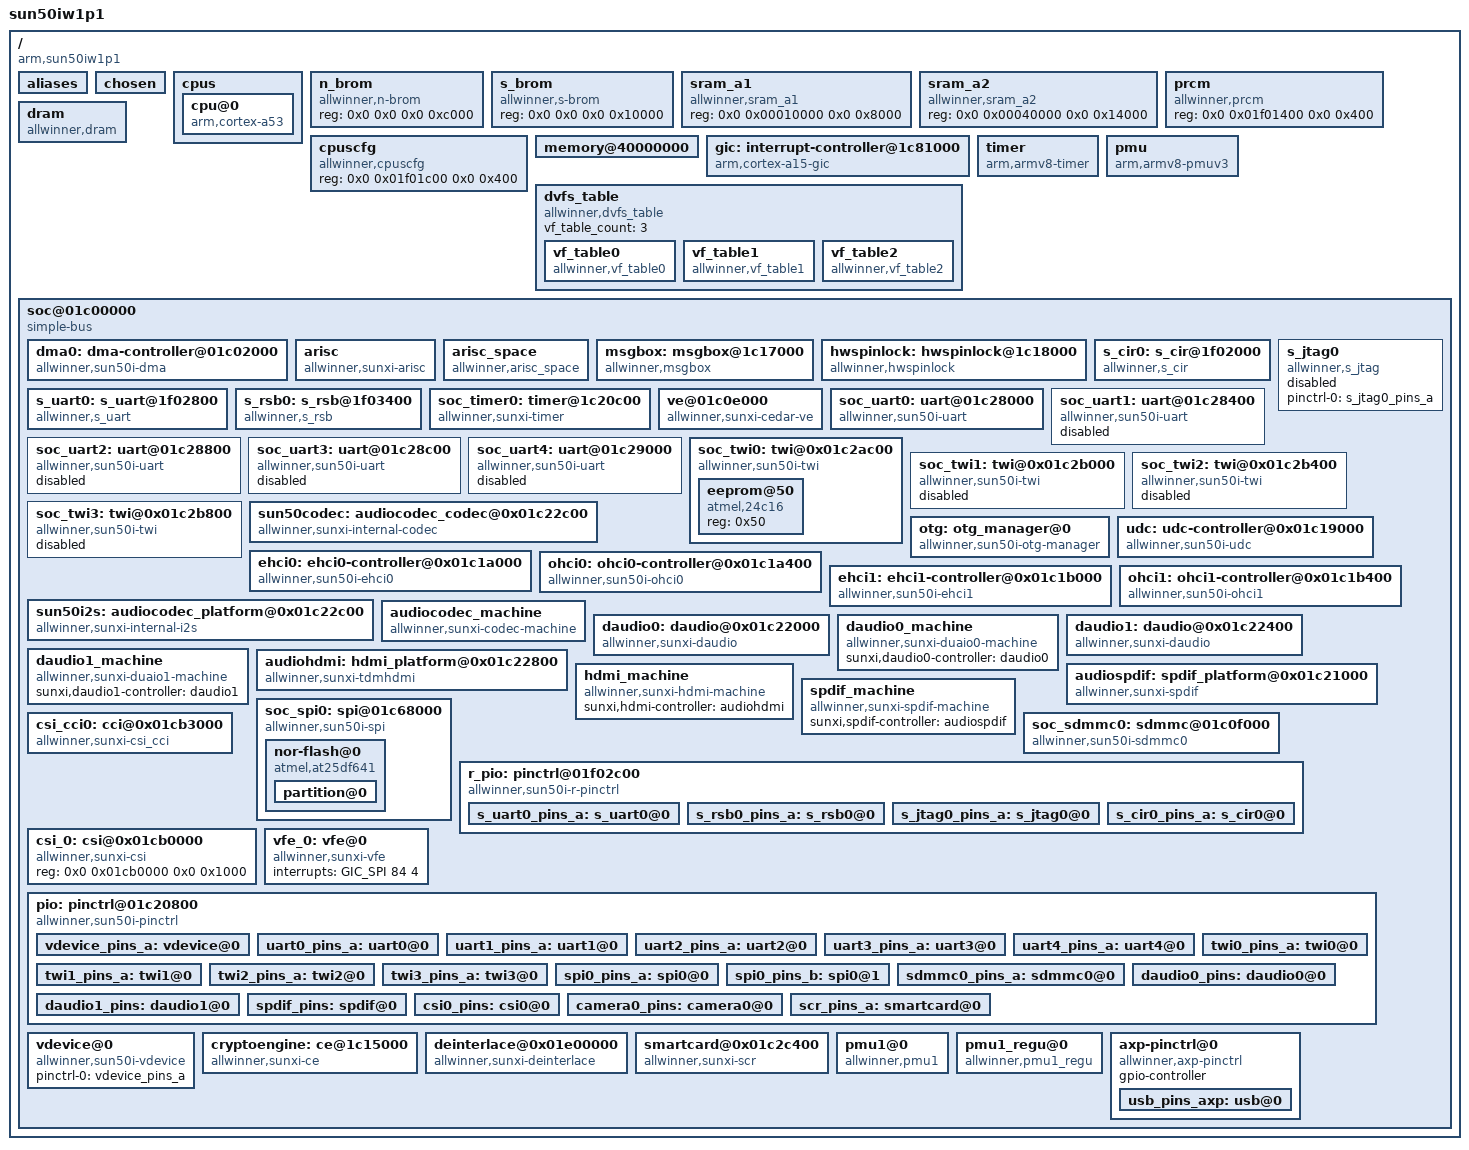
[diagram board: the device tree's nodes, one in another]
/*
 * Allwinner Technology CO., Ltd. sun50iw1p1 platform
 *
 * fpga support
 * modify base on juno.dts
 */

/dts-v1/;

/memreserve/ 0x40000000 0x00010000; /* sun50iw1p1.dtb range       : [0x40000000~0x40010000], size = 64K */
/memreserve/ 0x40010000 0x00010000; /* sys_config.fex range       : [0x40010000~0x40020000], size = 64K */
/memreserve/ 0x40020000 0x00004000; /* arisc dram code space range: [0x40020000~0x40024000], size = 16K */
/memreserve/ 0x40024000 0x00001000; /* arisc para cfg range       : [0x40024000~0x40025000], size = 4K  */
/memreserve/ 0x40025000 0x00000800; /* super standby range        : [0x40025000~0x40025800], size = 2K  */

#include <dt-bindings/interrupt-controller/arm-gic.h>
/include/"sun50iw1p1-clk.dtsi"

/ {
	model = "sun50iw1p1";
	compatible = "arm,sun50iw1p1", "arm,sun50iw1p1";
	interrupt-parent = <&gic>;
	#address-cells = <2>;
	#size-cells = <2>;

	aliases {
		serial0 = &soc_uart0;
		serial1 = &soc_uart1;
		serial2 = &soc_uart2;
		serial3 = &soc_uart3;
		serial4 = &soc_uart4;
		twi0 = &soc_twi0;
		twi1 = &soc_twi1;
		twi2 = &soc_twi2;
		twi3 = &soc_twi3;
		spi0 = &soc_spi0;
		global_timer0  = &soc_timer0;
		cci0 = &csi_cci0;
		csi0 = &csi_0;
		vfe0 = &vfe_0;
	};

	chosen {
		bootargs = "earlyprintk=sunxi-uart,0x01c28000 loglevel=8 initcall_debug=1 memblock=debug console=ttyS0 init=/init";
    };

	cpus {
		#address-cells = <2>;
		#size-cells = <0>;

		cpu@0 {
			device_type = "cpu";
			compatible = "arm,cortex-a53","arm,armv8";
			reg = <0x0 0x0>;
			enable-method = "psci";
			cpufreq_tbl = <  480000
							 600000
							 720000
							 816000
							1008000
							1200000
							1344000>;
			clock-latency = <2000000>;
		};
	};

	n_brom {
		compatible = "allwinner,n-brom";
		reg = <0x0 0x0 0x0 0xc000>;
	};

	s_brom {
		compatible = "allwinner,s-brom";
		reg = <0x0 0x0 0x0 0x10000>;
	};

	sram_a1 {
		compatible = "allwinner,sram_a1";
		reg = <0x0 0x00010000 0x0 0x8000>;
	};

	sram_a2 {
		compatible = "allwinner,sram_a2";
		reg = <0x0 0x00040000 0x0 0x14000>;
	};

	prcm {
		compatible = "allwinner,prcm";
		reg = <0x0 0x01f01400 0x0 0x400>;
	};

	cpuscfg {
		compatible = "allwinner,cpuscfg";
		reg = <0x0 0x01f01c00 0x0 0x400>;
	};

	dram {
		compatible = "allwinner,dram";
		clocks = <&clk_pll_ddr0>, <&clk_pll_ddr1>;
		clock-names = "pll_ddr0", "pll_ddr1";
		dram_clk        = <672>;
		dram_type       = <3>;
		dram_zq         = <0x003F3FDD>;
		dram_odt_en     = <1>;
		dram_para1      = <0x10f41000>;
		dram_para2      = <0x00001200>;
		dram_mr0        = <0x1A50>;
		dram_mr1        = <0x40>;
		dram_mr2        = <0x10>;
		dram_mr3        = <0>;
		dram_tpr0       = <0x04E214EA>;
		dram_tpr1       = <0x004214AD>;
		dram_tpr2       = <0x10A75030>;
		dram_tpr3       = <0>;
		dram_tpr4       = <0>;
		dram_tpr5       = <0>;
		dram_tpr6       = <0>;
		dram_tpr7       = <0>;
		dram_tpr8       = <0>;
		dram_tpr9       = <0>;
		dram_tpr10      = <0>;
		dram_tpr11      = <0>;
		dram_tpr12      = <168>;
		dram_tpr13      = <0x823>;
	};

	memory@40000000 {
		device_type = "memory";
		reg = <0x00000000 0x40000000 0x00000000 0x40000000>;
	};

	gic: interrupt-controller@1c81000 {
		compatible = "arm,cortex-a15-gic", "arm,cortex-a9-gic";
		#interrupt-cells = <3>;
		#address-cells = <0>;
		interrupt-controller;
		reg = <0x0 0x01c81000 0 0x1000>, /* GIC Dist */
		      <0x0 0x01c82000 0 0x2000>, /* GIC CPU */
		      <0x0 0x01c84000 0 0x2000>, /* GIC VCPU Control */
		      <0x0 0x01c86000 0 0x2000>; /* GIC VCPU */
		interrupts = <GIC_PPI 9 0xf04>; /* GIC Maintenence IRQ */
	};

	timer {
		compatible = "arm,armv8-timer";
		interrupts = <GIC_PPI 13 0xff01>, /* Secure Phys IRQ */
			     <GIC_PPI 14 0xff01>, /* Non-secure Phys IRQ */
			     <GIC_PPI 11 0xff01>, /* Virt IRQ */
			     <GIC_PPI 10 0xff01>; /* Hyp IRQ */
		clock-frequency = <24000000>;
	};

	pmu {
		compatible = "arm,armv8-pmuv3";
		interrupts = <GIC_SPI 120 4>,
			     <GIC_SPI 121 4>,
			     <GIC_SPI 122 4>,
			     <GIC_SPI 123 4>;
	};

	dvfs_table {
		compatible = "allwinner,dvfs_table";
		vf_table_count = <3>;

		vf_table0 {
			compatible = "allwinner,vf_table0";
			max_freq = <1200000000>;
			min_freq = <60000000>;
			LV_count = <8>;
			LV1_freq = <1200000000>;
			LV1_volt = <1300>;
			LV2_freq = <1104000000>;
			LV2_volt = <1200>;
			LV3_freq = <1008000000>;
			LV3_volt = <1100>;
			LV4_freq = <816000000>;
			LV4_volt = <1000>;
			LV5_freq = <600000000>;
			LV5_volt = <900>;
			LV6_freq = <0>;
			LV6_volt = <900>;
			LV7_freq = <0>;
			LV7_volt = <900>;
			LV8_freq = <0>;
			LV8_volt = <900>;
		};

		vf_table1 {
			compatible = "allwinner,vf_table1";
			max_freq = <1200000000>;
			min_freq = <60000000>;
			LV_count = <8>;
			LV1_freq = <1200000000>;
			LV1_volt = <1300>;
			LV2_freq = <1104000000>;
			LV2_volt = <1200>;
			LV3_freq = <1008000000>;
			LV3_volt = <1100>;
			LV4_freq = <816000000>;
			LV4_volt = <1000>;
			LV5_freq = <600000000>;
			LV5_volt = <900>;
			LV6_freq = <0>;
			LV6_volt = <900>;
			LV7_freq = <0>;
			LV7_volt = <900>;
			LV8_freq = <0>;
			LV8_volt = <900>;
		};

		vf_table2 {
			compatible = "allwinner,vf_table2";
			max_freq = <1200000000>;
			min_freq = <60000000>;
			LV_count = <8>;
			LV1_freq = <1200000000>;
			LV1_volt = <1300>;
			LV2_freq = <1104000000>;
			LV2_volt = <1200>;
			LV3_freq = <1008000000>;
			LV3_volt = <1100>;
			LV4_freq = <816000000>;
			LV4_volt = <1000>;
			LV5_freq = <600000000>;
			LV5_volt = <900>;
			LV6_freq = <0>;
			LV6_volt = <900>;
			LV7_freq = <0>;
			LV7_volt = <900>;
			LV8_freq = <0>;
			LV8_volt = <900>;
		};
	};

	soc@01c00000 {
		compatible = "simple-bus";
		#address-cells = <2>;
		#size-cells = <2>;
		ranges;

		dma0:dma-controller@01c02000 {
			compatible = "allwinner,sun50i-dma";
			reg = <0x0 0x01c02000 0x0 0x1000>;
			interrupts = <0 50 4>;
			clocks = <&clk_dma>;
			#dma-cells = <1>;
		};

		arisc {
			compatible = "allwinner,sunxi-arisc";
			#address-cells = <2>;
			#size-cells = <2>;
			clocks = <&clk_losc>, <&clk_iosc>, <&clk_hosc>, <&clk_pll_periph0>;
			clock-names = "losc", "iosc", "hosc", "pll_periph0";
			powchk_used = <0x0>;
			power_reg = <0x02309621>;
			system_power = <50>;
		};

		arisc_space {
			compatible = "allwinner,arisc_space";
			/* num    dst        offset     size                              */
			space1 = <0x00040000 0x00000000 0x00014000>; /* srama2 code space */
			space2 = <0x40020000 0x00018000 0x00004000>; /* dram code space   */
			space3 = <0x40024000 0x00000000 0x00001000>; /* para space        */
		};

		msgbox: msgbox@1c17000 {
			compatible = "allwinner,msgbox";
			clocks = <&clk_msgbox>;
			clock-names = "clk_msgbox";
			reg = <0x0 0x01c17000 0x0 0x1000>;
			interrupts = <GIC_SPI 49 IRQ_TYPE_EDGE_RISING>;
			status = "okay";
		};

		hwspinlock: hwspinlock@1c18000 {
			compatible = "allwinner,hwspinlock";
			clocks = <&clk_spinlock>;
			clock-names = "clk_spinlock";
			reg = <0x0 0x01c18000 0x0 0x1000>;
			status = "okay";
		};

		s_cir0: s_cir@1f02000 {
			compatible = "allwinner,s_cir";
			reg = <0x0 0x01f02000 0x0 0x400>;
			interrupts = <GIC_SPI 37 IRQ_TYPE_LEVEL_HIGH>;
			pinctrl-names = "default";
			pinctrl-0 = <&s_cir0_pins_a>;
			ir_power_key_code = <0>;
			ir_addr_code = <0>;
			status = "okay";
		};

		s_uart0: s_uart@1f02800 {
			compatible = "allwinner,s_uart";
			reg = <0x0 0x01f02800 0x0 0x400>;
			interrupts = <GIC_SPI 38 IRQ_TYPE_LEVEL_HIGH>;
			pinctrl-names = "default";
			pinctrl-0 = <&s_uart0_pins_a>;
			status = "okay";
		};

		s_rsb0: s_rsb@1f03400 {
			compatible = "allwinner,s_rsb";
			reg = <0x0 0x01f03400 0x0 0x400>;
			interrupts = <GIC_SPI 39 IRQ_TYPE_LEVEL_HIGH>;
			pinctrl-names = "default";
			pinctrl-0 = <&s_rsb0_pins_a>;
			status = "okay";
		};

		s_jtag0 {
			compatible = "allwinner,s_jtag";
			pinctrl-names = "default";
			pinctrl-0 = <&s_jtag0_pins_a>;
			status = "disable";
		};

		soc_timer0: timer@1c20c00 {
			compatible = "allwinner,sunxi-timer";
			reg = <0x0 0x01c20c00 0x0 0x90>;
			interrupts = <GIC_SPI 18 IRQ_TYPE_EDGE_RISING>;
			clock-frequency = <24000000>;
			timer-prescale = <16>;
		};

		ve@01c0e000 {		
			compatible = "allwinner,sunxi-cedar-ve";		
			reg = <0x0 0x01c0e000 0x0 0x1000>,
					<0x0 0x01c00000 0x0 0x10>,
					<0x0 0x01c20000 0x0 0x800>;		
			interrupts = <GIC_SPI 58 4>;
			clocks = <&clk_pll_ve>,		
							<&clk_ve>;				

		};

		soc_uart0: uart@01c28000 {
			compatible = "allwinner,sun50i-uart";
			reg = <0x0 0x01c28000 0x0 0x400>;
			interrupts = <GIC_SPI 0 IRQ_TYPE_LEVEL_HIGH>;
			clocks = <&clk_uart0>;
			pinctrl-names = "default";
			pinctrl-0 = <&uart0_pins_a>;
			port-number = <0>;
			io-number = <2>;
			status = "okay";
		};

		soc_uart1: uart@01c28400 {
			compatible = "allwinner,sun50i-uart";
			reg = <0x0 0x01c28400 0x0 0x400>;
			interrupts = <GIC_SPI 1 IRQ_TYPE_LEVEL_HIGH>;
			clocks = <&clk_uart1>;
			pinctrl-names = "default";
			pinctrl-0 = <&uart1_pins_a>;
			port-number = <1>;
			io-number = <4>;
			status = "disabled";
		};

		soc_uart2: uart@01c28800 {
			compatible = "allwinner,sun50i-uart";
			reg = <0x0 0x01c28800 0x0 0x400>;
			interrupts = <GIC_SPI 2 IRQ_TYPE_LEVEL_HIGH>;
			clocks = <&clk_uart2>;
			pinctrl-names = "default";
			pinctrl-0 = <&uart2_pins_a>;
			port-number = <1>;
			io-number = <4>;
			status = "disabled";
		};

		soc_uart3: uart@01c28c00 {
			compatible = "allwinner,sun50i-uart";
			reg = <0x0 0x01c28c00 0x0 0x400>;
			interrupts = <GIC_SPI 3 IRQ_TYPE_LEVEL_HIGH>;
			clocks = <&clk_uart3>;
			pinctrl-names = "default";
			pinctrl-0 = <&uart3_pins_a>;
			port-number = <1>;
			io-number = <4>;
			status = "disabled";
		};

		soc_uart4: uart@01c29000 {
			compatible = "allwinner,sun50i-uart";
			reg = <0x0 0x01c29000 0x0 0x400>;
			interrupts = <GIC_SPI 4 IRQ_TYPE_LEVEL_HIGH>;
			clocks = <&clk_uart4>;
			pinctrl-names = "default";
			pinctrl-0 = <&uart4_pins_a>;
			port-number = <1>;
			io-number = <4>;
			status = "disabled";
		};
		
		soc_twi0: twi@0x01c2ac00{
			#address-cells = <1>;
			#size-cells = <0>;
			compatible = "allwinner,sun50i-twi";
			reg = <0x0 0x01c2ac00 0x0 0x400>;
			interrupts = <GIC_SPI 6 IRQ_TYPE_LEVEL_HIGH>;
			clocks = <&clk_twi0>;
			clock-frequency = <400000>;
			pinctrl-names = "default";
			pinctrl-0 = <&twi0_pins_a>;
			status = "okay";

			eeprom@50 {
				compatible = "atmel,24c16";
				reg = <0x50>;
			};
		};

		soc_twi1: twi@0x01c2b000{
			#address-cells = <1>;
			#size-cells = <0>;
			compatible = "allwinner,sun50i-twi";
			reg = <0x0 0x01c2b000 0x0 0x400>;
			interrupts = <GIC_SPI 7 IRQ_TYPE_LEVEL_HIGH>;
			clocks = <&clk_twi1>;
			clock-frequency = <200000>;
			pinctrl-names = "default";
			pinctrl-0 = <&twi1_pins_a>;
			status = "disable";
		};

		soc_twi2: twi@0x01c2b400{
			#address-cells = <1>;
			#size-cells = <0>;
			compatible = "allwinner,sun50i-twi";
			reg = <0x0 0x01c2b400 0x0 0x400>;
			interrupts = <GIC_SPI 8 IRQ_TYPE_LEVEL_HIGH>;
			clocks = <&clk_twi2>;
			clock-frequency = <200000>;
			pinctrl-names = "default";
			pinctrl-0 = <&twi2_pins_a>;
			status = "disable";
		};

		soc_twi3: twi@0x01c2b800{
			#address-cells = <1>;
			#size-cells = <0>;
			compatible = "allwinner,sun50i-twi";
			reg = <0x0 0x01c2b800 0x0 0x400>;
			interrupts = <GIC_SPI 9 IRQ_TYPE_LEVEL_HIGH>;
			clocks = <&clk_twi3>;
			clock-frequency = <200000>;
			pinctrl-names = "default";
			pinctrl-0 = <&twi3_pins_a>;
			status = "disable";
		};
		sun50codec:audiocodec_codec@0x01c22c00 {
			compatible = "allwinner,sunxi-internal-codec";
			reg = <0x0 0x01c22c00 0x0 0x478>,/*digital baseadress*/
			      <0x0 0x01f015c0 0x0 0x0>;/*analog baseadress*/
			clocks = <&clk_pll_audiox4>;
			allwinner,headphonevol = /bits/ 8 <0x3b>;
			allwinner,spkervol = /bits/ 8 <0x1b>;
			allwinner,earpiecevol = /bits/ 8 <0x1e>;
			allwinner,maingain = /bits/ 8 <0x4>;
			allwinner,headsetmicgain = /bits/ 8 <0x4>;
			allwinner,adcagc_used = /bits/ 8 <0x0>;
			allwinner,adcdrc_used = /bits/ 8 <0x0>;
			allwinner,adchpf_used = /bits/ 8 <0x0>;
			allwinner,dacdrc_used = /bits/ 8 <0x0>;
			allwinner,dachpf_used = /bits/ 8 <0x0>;

			allwinner,aif2config = /bits/ 8 <0x0>;
			allwinner,aif3config = /bits/ 8 <0x0>;
			status = "okay";
		};

		otg:otg_manager@0 {
			compatible          = "allwinner,sun50i-otg-manager";
			usb_used            = <1>;
			usb_port_type       = <2>;
			usb_id_gpio         = <&pio 0 0 0>; /*PB0*/
			usb_det_vbus_gpio   = "axp_ctrl"; /*PB1*/
		};

		udc:udc-controller@0x01c19000 {
			compatible          = "allwinner,sun50i-udc";
			reg                 = <0x0 0x01c19000 0x0 0x1000>, /*udc base*/
			                      <0x0 0x01c00000 0x0 0x100>; /*sram base*/
			interrupts          = <0 71 4>;
			clocks              = <&clk_usbphy0>, <&clk_usbotg>;
			usb_used            = <1>;
			luns                = <3>;
			serial_unique       = <0>;
			serial_number       = "20080411";
		};

		ehci0:ehci0-controller@0x01c1a000 {
			compatible          = "allwinner,sun50i-ehci0";
			reg                 = <0x0 0x01c1a000 0x0 0x900>, /*udc base*/
			                      <0x0 0x01c00000 0x0 0x100>, /*sram base*/
			                      <0x0 0x01c19000 0x0 0x1000>; /*otg base*/
			interrupts          = <0 72 4>;
			clocks              = <&clk_usbphy0>, <&clk_usbehci0>;
			hci_ctrl_no         = <0>;
			usb_used            = <1>;
			usb_drv_vbus_gpio   = <&pio 0 0 0>; /*PA0*/
			usb_host_init_state = <0>;
			usb_regulator_io    = "nocare";
			usb_regulator_vol   = <0>;
			usb_wakeup_suspend  = <0>;
		};

		ohci0:ohci0-controller@0x01c1a400 {
			compatible          = "allwinner,sun50i-ohci0";
			reg                 = <0x0 0x01c1a400 0x0 0x500>, /*udc base*/
			                      <0x0 0x01c00000 0x0 0x100>, /*sram base*/
			                      <0x0 0x01c19000 0x0 0x1000>; /*otg base*/
			interrupts          = <0 73 4>;
			clocks              = <&clk_usbphy0>, <&clk_usbohci0>;
			hci_ctrl_no         = <0>;
			usb_used            = <1>;
			usb_drv_vbus_gpio   = <&pio 0 0 0>; /*PA0*/
			usb_host_init_state = <0>;
			usb_regulator_io    = "nocare";
			usb_regulator_vol   = <0>;
			usb_wakeup_suspend   = <0>;
		};

		ehci1:ehci1-controller@0x01c1b000 {
			compatible          = "allwinner,sun50i-ehci1";
			reg                 = <0x0 0x01c1b000 0x0 0x900>;/*udc base*/
			interrupts          = <0 74 4>;
			clocks              = <&clk_usbphy1>, <&clk_usbehci1>;
			hci_ctrl_no         = <1>;
			usb_used            = <1>;
			usb_drv_vbus_gpio   = <&pio 0 0 0>; /*PA1*/
			usb_host_init_state = <1>;
			usb_regulator_io    = "nocare";
			usb_regulator_vol   = <0>;
			usb_wakeup_suspend     = <0>;
		};

		ohci1:ohci1-controller@0x01c1b400 {
			compatible          = "allwinner,sun50i-ohci1";
			reg                 = <0x0 0x01c1b400 0x0 0x500>;/*udc base*/
			interrupts          = <0 75 4>;
			clocks              = <&clk_usbphy1>, <&clk_usbohci1>;
			hci_ctrl_no         = <1>;
			usb_used            = <1>;
			usb_drv_vbus_gpio   = <&pio 0 0 0>; /*PA1*/
			usb_host_init_state = <1>;
			usb_regulator_io    = "nocare";
			usb_regulator_vol   = <0>;
			usb_wakeup_suspend  = <0>;
		};

		sun50i2s:audiocodec_platform@0x01c22c00 {
			compatible = "allwinner,sunxi-internal-i2s";
			reg = <0x0 0x01c22c00 0x0 0x478>;/*digital baseadress*/
			clocks = <&clk_pll_audio>,<&clk_adda>;
			status = "okay";
		};

		audiocodec_machine{
			compatible = "allwinner,sunxi-codec-machine";
			interrupts = <GIC_SPI 61 0x101>;
			sunxi,i2s-controller = <&sun50i2s>;
			sunxi,audio-codec = <&sun50codec>;
			status = "okay";
		};

		daudio0:daudio@0x01c22000 {
			compatible = "allwinner,sunxi-daudio";
			reg = <0x0 0x01c22000 0x0 0x58>;
			clocks = <&clk_pll_audio>,<&clk_i2s0>;
			pinctrl-names = "default";
			pinctrl-0 = <&daudio0_pins>;
			allwinner,pcm_lrck_period = /bits/ 8 <0x20>;
			allwinner,pcm_lrckr_period = /bits/ 8 <0x01>;
			allwinner,slot_width_select = /bits/ 8 <0x10>;
			allwinner,pcm_lsb_first = /bits/ 8 <0x0>;
			allwinner,tx_data_mode = /bits/ 8 <0x0>;
			allwinner,rx_data_mode = /bits/ 8 <0x0>;
			allwinner,daudio_master = /bits/ 8 <0x04>;
			allwinner,audio_format = /bits/ 8 <0x01>;
			allwinner,signal_inversion = /bits/ 8 <0x01>;
			allwinner,frametype = /bits/ 8 <0x0>;
			allwinner,tdm_config = /bits/ 8 <0x01>;
			status = "okay";
		};
		daudio0_machine{
			compatible = "allwinner,sunxi-duaio0-machine";
			sunxi,daudio0-controller = <&daudio0>;
			status = "okay";
		};
		daudio1:daudio@0x01c22400 {
			compatible = "allwinner,sunxi-daudio";
			reg = <0x0 0x01c22400 0x0 0x58>;
			pinctrl-names = "default";
			pinctrl-0 = <&daudio1_pins>;
			clocks = <&clk_pll_audio>,<&clk_i2s1>;
			allwinner,pcm_lrck_period = /bits/ 8 <0x20>;
			allwinner,pcm_lrckr_period = /bits/ 8 <0x01>;
			allwinner,slot_width_select = /bits/ 8 <0x10>;
			allwinner,pcm_lsb_first = /bits/ 8 <0x0>;
			allwinner,tx_data_mode = /bits/ 8 <0x0>;
			allwinner,rx_data_mode = /bits/ 8 <0x0>;
			allwinner,daudio_master = /bits/ 8 <0x04>;
			allwinner,audio_format = /bits/ 8 <0x01>;
			allwinner,signal_inversion = /bits/ 8 <0x01>;
			allwinner,frametype = /bits/ 8 <0x0>;
			allwinner,tdm_config = /bits/ 8 <0x01>;
			status = "okay";
		};
		daudio1_machine{
			compatible = "allwinner,sunxi-duaio1-machine";
			sunxi,daudio1-controller = <&daudio1>;
			status = "okay";
		};
		audiohdmi:hdmi_platform@0x01c22800{
			compatible = "allwinner,sunxi-tdmhdmi";
			reg = <0x0 0x01c22800 0x0 0x58>;
			clocks = <&clk_pll_audio>,<&clk_i2s2>;
			status = "okay";
		};
		hdmi_machine{
			compatible = "allwinner,sunxi-hdmi-machine";
			sunxi,hdmi-controller = <&audiohdmi>;
			status = "okay";
		};
		audiospdif:spdif_platform@0x01c21000{
			compatible = "allwinner,sunxi-spdif";
			reg = <0x0 0x01c21000 0x0 0x38>;
			clocks = <&clk_pll_audio>,<&clk_spdif>;
			pinctrl-names = "default";
			pinctrl-0 = <&spdif_pins>;
			status = "okay";
		};
		spdif_machine{
			compatible = "allwinner,sunxi-spdif-machine";
			sunxi,spdif-controller = <&audiospdif>;
			status = "okay";
		};
	
		soc_spi0: spi@01c68000 {
			#address-cells = <1>;
			#size-cells = <0>;
			compatible = "allwinner,sun50i-spi";
			reg = <0x0 0x01c68000 0x0 0x1000>;
			interrupts = <GIC_SPI 65 IRQ_TYPE_LEVEL_HIGH>;
			clocks = <&clk_pll_periph0>, <&clk_spi0>;
			pinctrl-names = "default";
			pinctrl-0 = <&spi0_pins_a>, <&spi0_pins_b>;
			cs-number = <1>;
			cs-bitmap = <1>;
			status = "okay";

			nor-flash@0 {
				#address-cells = <1>;
				#size-cells = <1>;
				compatible = "atmel,at25df641";
				reg = <0>;	/* Chip select 0 */
				spi-max-frequency = <50000000>;
				mode = <0>;

				partition@0 {
					label = "NorFlash part0";
					reg = <0x00000000 0x0002000>;
				};
			};
		};

		soc_sdmmc0: sdmmc@01c0f000 {
			compatible = "allwinner,sun50i-sdmmc0";
			reg = <0x0 0x01c0f000 0x0 0x1000>; /* only sdmmc0 */
			interrupts = <GIC_SPI 60 0x0104>;  /*  */
			clocks = <&clk_hosc>,<&clk_pll_periph0>,<&clk_sdmmc0>;
			pinctrl-names = "default";
			pinctrl-0 = <&sdmmc0_pins_a>;
			status = "okay";
		};
		r_pio: pinctrl@01f02c00 {
			compatible = "allwinner,sun50i-r-pinctrl";
			reg = <0x0 0x01f02c00 0x0 0x400>;
			interrupts = <GIC_SPI 35 4>;
			clocks = <&clk_cpurpio>;
			//resets = <&apb0_rst 0>;
			gpio-controller;
			interrupt-controller;
			#interrupt-cells = <2>;
			#size-cells = <0>;
			#gpio-cells = <3>;

			s_uart0_pins_a: s_uart0@0 {
				allwinner,pins = "PL2", "PL3";
				allwinner,function = "s_uart0";
				allwinner,drive = <1>;
				allwinner,pull = <1>;
			};

			s_rsb0_pins_a: s_rsb0@0 {
				allwinner,pins = "PL0", "PL1";
				allwinner,function = "s_rsb0";
				allwinner,drive = <2>;
				allwinner,pull = <1>;
			};

			s_jtag0_pins_a: s_jtag0@0 {
				allwinner,pins = "PL4", "PL5", "PL6", "PL7";
				allwinner,function = "s_jtag0";
				allwinner,drive = <2>;
				allwinner,pull = <1>;
			};

			s_cir0_pins_a: s_cir0@0 {
				allwinner,pins = "PL11";
				allwinner,function = "s_cir0";
				allwinner,drive = <2>;
				allwinner,pull = <1>;
			};
		};
		
		csi_cci0:cci@0x01cb3000 {
			compatible = "allwinner,sunxi-csi_cci";
			reg = <0x0 0x01cb3000 0x0 0x1000>;	/*0x01cb3000--0x01cb4000*/
			interrupts = <GIC_SPI 122 4>;/*SUNXI_IRQ_CSI0_CCI (SUNXI_GIC_START + 122)*/
			status = "okay";
		};		
		csi_0:csi@0x01cb0000 {
			compatible = "allwinner,sunxi-csi";
			reg = <0x0 0x01cb0000 0x0 0x1000>;/*0x01cb0000--0x01cb1000*/
			status = "okay";
		};
		vfe_0:vfe@0 {
			compatible = "allwinner,sunxi-vfe";
			interrupts = <GIC_SPI 84 4>;/*SUNXI_IRQ_CSI0 (SUNXI_GIC_START + 84 )*/
			status = "okay";
		};
		
		pio: pinctrl@01c20800 {
			compatible = "allwinner,sun50i-pinctrl";
			reg = <0x0 0x01c20800 0x0 0x400>;
			interrupts =	<GIC_SPI 11 4>,
					<GIC_SPI 17 4>,
					<GIC_SPI 21 4>;
			clocks = <&clk_pio>;
			gpio-controller;
			interrupt-controller;
			#interrupt-cells = <2>;
			#size-cells = <0>;
			#gpio-cells = <3>;
			vdevice_pins_a: vdevice@0 {
				allwinner,pins = "PB0", "PB1";
				allwinner,function = "vdevice";
				allwinner,drive = <1>;
				allwinner,pull = <1>;
			};
			uart0_pins_a: uart0@0 {
				allwinner,pins = "PB8", "PB9";
				allwinner,function = "uart0";
				allwinner,drive = <1>;
				allwinner,pull = <0>;
			};
			uart1_pins_a: uart1@0 {
				allwinner,pins = "PG6", "PG7", "PG8", "PG9";
				allwinner,function = "uart1";
				allwinner,drive = <1>;
				allwinner,pull = <0>;
			};
			uart2_pins_a: uart2@0 {
				allwinner,pins = "PB0", "PB1", "PB2", "PB3";
				allwinner,function = "uart2";
				allwinner,drive = <1>;
				allwinner,pull = <0>;
			};
			uart3_pins_a: uart3@0 {
				allwinner,pins = "PH4", "PH5", "PH6", "PH7";
				allwinner,function = "uart3";
				allwinner,drive = <1>;
				allwinner,pull = <0>;
			};
			uart4_pins_a: uart4@0 {
				allwinner,pins = "PD2", "PD3", "PD4", "PD5";
				allwinner,function = "uart4";
				allwinner,drive = <1>;
				allwinner,pull = <0>;
			};

			twi0_pins_a: twi0@0 {
				//allwinner,pins = "PH0", "PH1";
				allwinner,pins = "PB0", "PB1";	// for fpga
				allwinner,function = "twi0";
				allwinner,drive = <1>;
				allwinner,pull = <0>;
			};
			twi1_pins_a: twi1@0 {
				allwinner,pins = "PH2", "PH3";
				allwinner,function = "twi1";
				allwinner,drive = <1>;
				allwinner,pull = <0>;
			};
			twi2_pins_a: twi2@0 {
				allwinner,pins = "PE14", "PE15";
				allwinner,function = "twi2";
				allwinner,drive = <1>;
				allwinner,pull = <0>;
			};
			twi3_pins_a: twi3@0 {
				allwinner,pins = "PE16", "PE17";
				allwinner,function = "twi3";
				allwinner,drive = <1>;
				allwinner,pull = <0>;
			};
			spi0_pins_a: spi0@0 {
				allwinner,pins = "PC0", "PC1", "PC2";
				allwinner,function = "spi0";
				allwinner,drive = <1>;
				allwinner,pull = <0>;
			};
			spi0_pins_b: spi0@1 {
				allwinner,pins = "PC3";
				allwinner,function = "spi0";
				allwinner,drive = <1>;
				allwinner,pull = <1>; 	// only CS should be pulled up
			};

			sdmmc0_pins_a: sdmmc0@0 {
				allwinner,pins = "PF0", "PF1", "PF2", "PF3","PF4","PF5";
				allwinner,function = "sdc0";
				allwinner,drive = <1>;
				allwinner,pull = <1>;
			};		
			daudio0_pins: daudio0@0 {
				allwinner,pins = "PB6", "PB3", "PB4", "PB5", "PB7";
				allwinner,function = "pcm0";
				allwinner,drive = <1>;
				allwinner,pull = <0>;
			};
			daudio1_pins: daudio1@0 {
				allwinner,pins = "PG10", "PG11", "PG12", "PG13";
				allwinner,function = "pcm1";
				allwinner,drive = <1>;
				allwinner,pull = <0>;
			};	
			spdif_pins: spdif@0 {
				allwinner,pins = "PH8";/*ph8-spec*/
				allwinner,function = "spdif0";
				allwinner,drive = <1>;
				allwinner,pull = <0>;
			};		
			csi0_pins: csi0@0 {
				allwinner,pins = "PE0","PE1","PE2","PE3","PE4","PE5","PE6","PE7","PE8","PE9","PE10","PE11","PE12","PE13";
				allwinner,function = "csi0";
				allwinner,drive = <1>;
				allwinner,pull = <0>;
			};
			camera0_pins: camera0@0 {
				allwinner,pins = "PE16","PE17";
				allwinner,function = "gpio_out";
				allwinner,drive = <1>;
				allwinner,pull = <0>;
			};						
			scr_pins_a: smartcard@0 {
				allwinner,pins = "PB1", "PB4", "PB5", "PB6","PB7";
				allwinner,function = "sim0";
				allwinner,drive = <1>;
				allwinner,pull = <1>;
			};
		};
		vdevice@0{
			compatible = "allwinner,sun50i-vdevice";
			pinctrl-names = "default";
			pinctrl-0 = <&vdevice_pins_a>;
			status = "okay";
		};
		cryptoengine: ce@1c15000 {
			compatible = "allwinner,sunxi-ce";
			reg = <0x0 0x01c15000 0x0 0x80>, /* non-secure space */
				  <0x0 0x01c15800 0x0 0x80>; /* secure space */
			interrupts = <GIC_SPI 94 0xff01>, /* non-secure space */
						 <GIC_SPI 80 0xff01>; /* secure space */
			clock-frequency = <300000000>, /* 300MHz */
							  <200000000>; /* 200MHz for RSA */
			clocks = <&clk_ce>,
					 <&clk_pll_periph0>;
		};
		deinterlace@0x01e00000{
			#address-cells = <1>;
			#size-cells = <0>;
			compatible = "allwinner,sunxi-deinterlace";
			reg = <0x0 0x01e00000 0x0 0x77c>;
			interrupts = <GIC_SPI 93 IRQ_TYPE_LEVEL_HIGH>;
			clocks = <&clk_deinterlace> ,<&clk_pll_periph0>;
			status = "okay";
		};
		smartcard@0x01c2c400{
			#address-cells = <1>;
			#size-cells = <0>;
			compatible = "allwinner,sunxi-scr";
			reg = <0x0 0x01c2c400 0x0 0x77c>;
			interrupts = <GIC_SPI 83 IRQ_TYPE_LEVEL_HIGH>;
			clocks = <&clk_scr>, <&clk_apb2>;
			clock-frequency = <24000000>;
			pinctrl-names = "default";
			pinctrl-0 = <&scr_pins_a>;
			status = "okay";
		};
		pmu1@0{
			compatible = "allwinner,pmu1";
			pmu_batdeten               = <1>;
			pmu_init_chgend_rate       = <20>;
			pmu_init_chg_enabled       = <1>;
			pmu_init_adc_freq          = <800>;
			pmu_init_adcts_freq        = <800>;
			pmu_init_chg_pretime       = <70>;
			pmu_init_chg_csttime       = <720>;
			pmu_batt_cap_correct       = <1>;
			pmu_chg_end_on_en          = <0>;

			pmu_pwroff_vol             = <3300>;
			pmu_pwron_vol              = <2600>;
			pmu_powkey_off_delay_time  = <0>;
			pmu_pwrok_time             = <64>;
			pmu_reset_shutdown_en      = <1>;
			pmu_restvol_adjust_time    = <60>;
			pmu_ocv_cou_adjust_time    = <60>;
			pmu_vbusen_func            = <1>;
			pmu_reset                  = <0>;
			pmu_IRQ_wakeup             = <0>;
			pmu_hot_shutdowm           = <1>;
			pmu_inshort                = <0>;
			pmu_bat_shutdown_ltf       = <3200>; /* add by superm for debug */
			pmu_bat_shutdown_htf       = <237>;  /* add by superm for debug */
			status = "okay";
		};
		pmu1_regu@0{
			compatible = "allwinner,pmu1_regu";
			regulator_count = <23>;
			regulator1      = "axp81x_dcdc1 none vcc-nand vcc-nor vcc-usb0-33 vcc-card vcc-io vcc-wifi-io vcc-io1 vcc-io2 vcc-sensor vcc-camera-33";
			regulator2      = "axp81x_dcdc2 none vdd-cpua";
			regulator3      = "axp81x_dcdc3 none vdd-cpub";
			regulator4      = "axp81x_dcdc4 none vdd-gpu";
			regulator5      = "axp81x_dcdc5 none vcc-dram";
			regulator6      = "axp81x_dcdc6 none vdd-sys vdd-usb0-09 vdd-hdmi-09";
			regulator7      = "axp81x_dcdc7 none";
			regulator8      = "axp81x_rtc none";
			regulator9      = "axp81x_aldo1 none avdd-csi";
			regulator10     = "axp81x_aldo2 none afvcc-csi iovdd-csi";
			regulator11     = "axp81x_aldo3 none vcc-avcc vcc-pl";
			regulator12     = "axp81x_dldo1 none vcc-vibrator dvdd-ephy";
			regulator13     = "axp81x_dldo2 none vcc-mipi";
			regulator14     = "axp81x_dldo3 none vdd-drampll vdd-lpddr-18 vcc-pll vcc-adc vcc-cpvdd vcc-ldoin";
			regulator15     = "axp81x_dldo4 none vcc-ephy-io vcc-pd";
			regulator16     = "axp81x_eldo1 1 dvdd-csi-18";
			regulator17     = "axp81x_eldo2 1 vcc-dsi-18 vcc-csi2-18 vcc-lvds-18 vcc-efuse-18 vcc-hdmi-18";
			regulator18     = "axp81x_eldo3 1";
			regulator19     = "axp81x_fldo1 none avdd-ephy, vcc-hsic-12";
			regulator20     = "axp81x_fldo2 none vdd-cpus";
			regulator21     = "axp81x_gpio0ldo none";
			regulator22     = "axp81x_gpio1ldo none vcc-ctp";
			regulator23     = "axp81x_dc1sw 1 vcc-lcd-0";
			status = "okay";
		};
		axp-pinctrl@0 {
			compatible = "allwinner,axp-pinctrl";
			gpio-controller;
			#size-cells = <0>;
			#gpio-cells = <3>;
			usb_pins_axp: usb@0 {
				allwinner,pins = "power3";
				allwinner,function = "gpio_out";
				allwinner,drive = <1>;
				allwinner,pull = <1>;
			};
		};
	};
};
